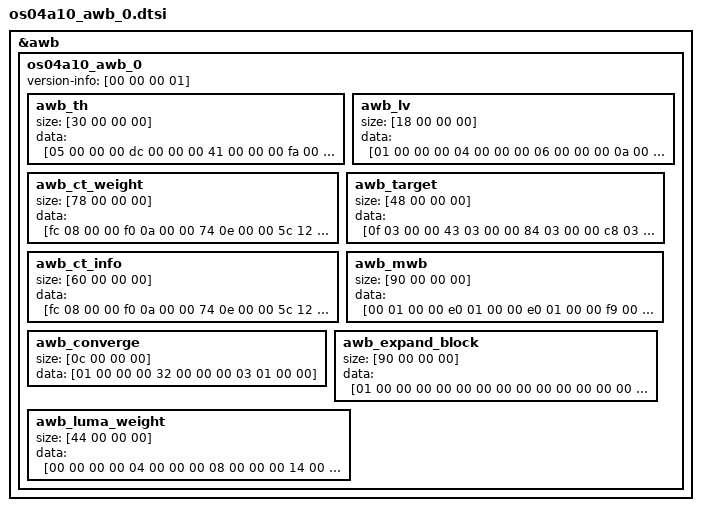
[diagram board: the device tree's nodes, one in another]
/*
 * Novatek Ltd. NVT98538 ISP part of dts
 */

&awb {
	os04a10_awb_0 {
		version-info = [00 00 00 01];
		awb_th {
			size = [30 00 00 00];
			data = [05 00 00 00 dc 00 00 00 41 00 00 00 fa 00 00 00 d4 ff ff ff 82 00 00 00 2c 00 00 00 a4 00 00 00 15 00 00 00 56 00 00 00 17 00 00 00 2b 00 00 00];
		};
		awb_lv {
			size = [18 00 00 00];
			data = [01 00 00 00 04 00 00 00 06 00 00 00 0a 00 00 00 0e 00 00 00 1a 00 00 00];
		};
		awb_ct_weight {
			size = [78 00 00 00];
			data = [fc 08 00 00 f0 0a 00 00 74 0e 00 00 5c 12 00 00 64 19 00 00 f8 2a 00 00 0f 03 00 00 43 03 00 00 84 03 00 00 c8 03 00 00 16 04 00 00 60 04 00 00 01 00 00 00 01 00 00 00 01 00 00 00 01 00 00 00 01 00 00 00 01 00 00 00 01 00 00 00 01 00 00 00 01 00 00 00 01 00 00 00 01 00 00 00 01 00 00 00 01 00 00 00 01 00 00 00 01 00 00 00 01 00 00 00 01 00 00 00 01 00 00 00];
		};
		awb_target {
			size = [48 00 00 00];
			data = [0f 03 00 00 43 03 00 00 84 03 00 00 c8 03 00 00 16 04 00 00 60 04 00 00 00 04 00 00 00 04 00 00 00 04 00 00 00 04 00 00 00 04 00 00 00 04 00 00 00 04 00 00 00 04 00 00 00 04 00 00 00 04 00 00 00 04 00 00 00 04 00 00];
		};
		awb_ct_info {
			size = [60 00 00 00];
			data = [fc 08 00 00 f0 0a 00 00 74 0e 00 00 5c 12 00 00 64 19 00 00 f8 2a 00 00 fc 00 00 00 22 01 00 00 67 01 00 00 ad 01 00 00 fb 01 00 00 8d 02 00 00 00 01 00 00 00 01 00 00 00 01 00 00 00 01 00 00 00 01 00 00 00 01 00 00 0f 04 00 00 66 03 00 00 f0 02 00 00 55 02 00 00 bf 01 00 00 78 01 00 00];
		};
		awb_mwb {
			size = [90 00 00 00];
			data = [00 01 00 00 e0 01 00 00 e0 01 00 00 f9 00 00 00 1d 01 00 00 00 01 00 00 00 01 00 00 00 01 00 00 00 01 00 00 00 01 00 00 00 01 00 00 00 01 00 00 00 01 00 00 00 01 00 00 00 01 00 00 00 01 00 00 00 01 00 00 00 01 00 00 00 01 00 00 00 01 00 00 00 01 00 00 00 01 00 00 00 01 00 00 00 01 00 00 00 01 00 00 79 01 00 00 40 01 00 00 47 03 00 00 26 03 00 00 00 01 00 00 00 01 00 00 00 01 00 00 00 01 00 00 00 01 00 00 00 01 00 00 00 01 00 00];
		};
		awb_converge {
			size = [0c 00 00 00];
			data = [01 00 00 00 32 00 00 00 03 01 00 00];
		};
		awb_expand_block {
			size = [90 00 00 00];
			data = [01 00 00 00 00 00 00 00 00 00 00 00 00 00 00 00 06 00 00 00 06 00 00 00 06 00 00 00 06 00 00 00 0a 00 00 00 0a 00 00 00 0a 00 00 00 0a 00 00 00 05 00 00 00 05 00 00 00 05 00 00 00 05 00 00 00 f5 00 00 00 f5 00 00 00 f5 00 00 00 f5 00 00 00 6a 00 00 00 69 00 00 00 5b 00 00 00 72 00 00 00 77 00 00 00 7a 00 00 00 69 00 00 00 80 00 00 00 19 00 00 00 38 00 00 00 12 00 00 00 20 00 00 00 26 00 00 00 4a 00 00 00 20 00 00 00 cb ff ff ff];
		};
		awb_luma_weight {
			size = [44 00 00 00];
			data = [00 00 00 00 04 00 00 00 08 00 00 00 14 00 00 00 20 00 00 00 c0 00 00 00 d0 00 00 00 e0 00 00 00 f0 00 00 00 01 00 00 00 01 00 00 00 01 00 00 00 01 00 00 00 01 00 00 00 01 00 00 00 01 00 00 00 01 00 00 00];
		};
	};
};
